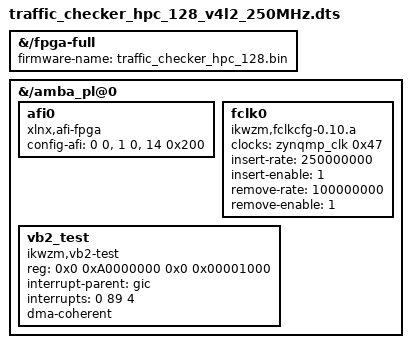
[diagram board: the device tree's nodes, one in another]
/dts-v1/; /plugin/;
/ {
	fragment@0 {
		target-path = "/fpga-full";
		__overlay__ {
			firmware-name = "traffic_checker_hpc_128.bin";
		};
        };
	fragment@1 {
		target-path = "/amba_pl@0";
		__overlay__ {
			afi0 {
				compatible    = "xlnx,afi-fpga";
				config-afi    = <0 0>, <1 0>, <14 0x200>;
			};
			fclk0 {
				compatible    = "ikwzm,fclkcfg-0.10.a";
				clocks        = <&zynqmp_clk 0x47>;
				insert-rate   = "250000000";
				insert-enable = <1>;
				remove-rate   = "100000000";
				remove-enable = <1>;
			};
		};
	};
	fragment@2 {
		target-path = "/amba_pl@0";
		#address-cells = <2>;
		#size-cells = <2>;

		__overlay__ {
			#address-cells = <2>;
			#size-cells = <2>;

			vb2_test {
				compatible = "ikwzm,vb2-test";
				reg = <0x0 0xA0000000 0x0 0x00001000>;
				interrupt-parent = <&gic>;
				interrupts = <0 89 4>;
				dma-coherent;
	                };
                };
	} ;
} ;
